# iqn_ail register map
Vendor: Texas Instruments
Registers are 32-bit, read-only, no defined reset value unless marked. A register's access mark holds for its fields unless they carry their own. Offsets are as the file gives them; [hi:lo] are bit positions; {n}, {i} and the like mark numbered series.

## IQN_AIL (part 3 of 5)
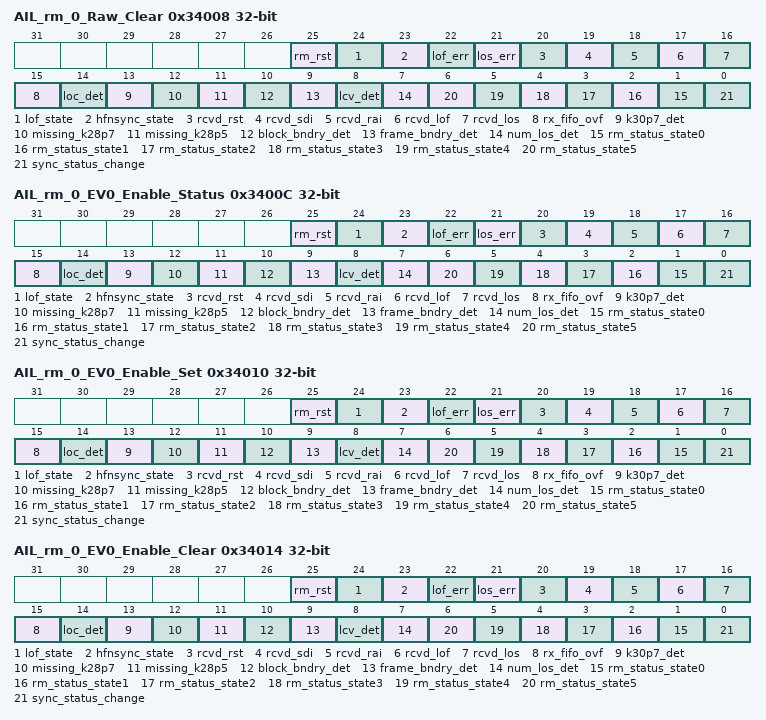
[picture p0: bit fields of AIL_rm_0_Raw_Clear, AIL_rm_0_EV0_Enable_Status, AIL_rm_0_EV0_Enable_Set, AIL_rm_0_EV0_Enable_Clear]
0x34008 AIL_rm_0_Raw_Clear wo — (1 of 1, stride 0)
  [25] rm_rst — Clears the corresponding bit in the raw_status register when set. Write only, self-clears.
  [24] lof_state — Clears the corresponding bit in the raw_status register when set. Write only, self-clears.
  [23] hfnsync_state — Clears the corresponding bit in the raw_status register when set. Write only, self-clears.
  [22] lof_err — Clears the corresponding bit in the raw_status register when set. Write only, self-clears.
  [21] los_err — Clears the corresponding bit in the raw_status register when set. Write only, self-clears.
  [20] rcvd_rst — Clears the corresponding bit in the raw_status register when set. Write only, self-clears.
  [19] rcvd_sdi — Clears the corresponding bit in the raw_status register when set. Write only, self-clears.
  [18] rcvd_rai — Clears the corresponding bit in the raw_status register when set. Write only, self-clears.
  [17] rcvd_lof — Clears the corresponding bit in the raw_status register when set. Write only, self-clears.
  [16] rcvd_los — Clears the corresponding bit in the raw_status register when set. Write only, self-clears.
  [15] rx_fifo_ovf — Clears the corresponding bit in the raw_status register when set. Write only, self-clears.
  [14] loc_det — Clears the corresponding bit in the raw_status register when set. Write only, self-clears.
  [13] k30p7_det — Clears the corresponding bit in the raw_status register when set. Write only, self-clears.
  [12] missing_k28p7 — Clears the corresponding bit in the raw_status register when set. Write only, self-clears.
  [11] missing_k28p5 — Clears the corresponding bit in the raw_status register when set. Write only, self-clears.
  [10] block_bndry_det — Clears the corresponding bit in the raw_status register when set. Write only, self-clears.
  [9] frame_bndry_det — Clears the corresponding bit in the raw_status register when set. Write only, self-clears.
  [8] lcv_det — Clears the corresponding bit in the raw_status register when set. Write only, self-clears.
  [7] num_los_det — Clears the corresponding bit in the raw_status register when set. Write only, self-clears.
  [n+1] rm_status_state{n} (n=0..5) — Clears the corresponding bit in the raw_status register when set. Write only, self-clears.
  [0] sync_status_change — Clears the corresponding bit in the raw_status register when set. Write only, self-clears.
0x3400C AIL_rm_0_EV0_Enable_Status — (1 of 1, stride 0)
  [25] rm_rst — When set allows the corresponding bit in the raw_status register to generate the intr_sts interrupt. Read only.
  [24] lof_state — When set allows the corresponding bit in the raw_status register to generate the intr_sts interrupt. Read only.
  [23] hfnsync_state — When set allows the corresponding bit in the raw_status register to generate the intr_sts interrupt. Read only.
  [22] lof_err — When set allows the corresponding bit in the raw_status register to generate the intr_sts interrupt. Read only.
  [21] los_err — When set allows the corresponding bit in the raw_status register to generate the intr_sts interrupt. Read only.
  [20] rcvd_rst — When set allows the corresponding bit in the raw_status register to generate the intr_sts interrupt. Read only.
  [19] rcvd_sdi — When set allows the corresponding bit in the raw_status register to generate the intr_sts interrupt. Read only.
  [18] rcvd_rai — When set allows the corresponding bit in the raw_status register to generate the intr_sts interrupt. Read only.
  [17] rcvd_lof — When set allows the corresponding bit in the raw_status register to generate the intr_sts interrupt. Read only.
  [16] rcvd_los — When set allows the corresponding bit in the raw_status register to generate the intr_sts interrupt. Read only.
  [15] rx_fifo_ovf — When set allows the corresponding bit in the raw_status register to generate the intr_sts interrupt. Read only.
  [14] loc_det — When set allows the corresponding bit in the raw_status register to generate the intr_sts interrupt. Read only.
  [13] k30p7_det — When set allows the corresponding bit in the raw_status register to generate the intr_sts interrupt. Read only.
  [12] missing_k28p7 — When set allows the corresponding bit in the raw_status register to generate the intr_sts interrupt. Read only.
  [11] missing_k28p5 — When set allows the corresponding bit in the raw_status register to generate the intr_sts interrupt. Read only.
  [10] block_bndry_det — When set allows the corresponding bit in the raw_status register to generate the intr_sts interrupt. Read only.
  [9] frame_bndry_det — When set allows the corresponding bit in the raw_status register to generate the intr_sts interrupt. Read only.
  [8] lcv_det — When set allows the corresponding bit in the raw_status register to generate the intr_sts interrupt. Read only.
  [7] num_los_det — When set allows the corresponding bit in the raw_status register to generate the intr_sts interrupt. Read only.
  [n+1] rm_status_state{n} (n=0..5) — When set allows the corresponding bit in the raw_status register to generate the intr_sts interrupt. Read only.
  [0] sync_status_change — When set allows the corresponding bit in the raw_status register to generate the intr_sts interrupt. Read only.
0x34010 AIL_rm_0_EV0_Enable_Set wo — (1 of 1, stride 0)
  [25] rm_rst — Sets the corresponding bit in the enable register when set. Write only, self-clears.
  [24] lof_state — Sets the corresponding bit in the enable register when set. Write only, self-clears.
  [23] hfnsync_state — Sets the corresponding bit in the enable register when set. Write only, self-clears.
  [22] lof_err — Sets the corresponding bit in the enable register when set. Write only, self-clears.
  [21] los_err — Sets the corresponding bit in the enable register when set. Write only, self-clears.
  [20] rcvd_rst — Sets the corresponding bit in the enable register when set. Write only, self-clears.
  [19] rcvd_sdi — Sets the corresponding bit in the enable register when set. Write only, self-clears.
  [18] rcvd_rai — Sets the corresponding bit in the enable register when set. Write only, self-clears.
  [17] rcvd_lof — Sets the corresponding bit in the enable register when set. Write only, self-clears.
  [16] rcvd_los — Sets the corresponding bit in the enable register when set. Write only, self-clears.
  [15] rx_fifo_ovf — Sets the corresponding bit in the enable register when set. Write only, self-clears.
  [14] loc_det — Sets the corresponding bit in the enable register when set. Write only, self-clears.
  [13] k30p7_det — Sets the corresponding bit in the enable register when set. Write only, self-clears.
  [12] missing_k28p7 — Sets the corresponding bit in the enable register when set. Write only, self-clears.
  [11] missing_k28p5 — Sets the corresponding bit in the enable register when set. Write only, self-clears.
  [10] block_bndry_det — Sets the corresponding bit in the enable register when set. Write only, self-clears.
  [9] frame_bndry_det — Sets the corresponding bit in the enable register when set. Write only, self-clears.
  [8] lcv_det — Sets the corresponding bit in the enable register when set. Write only, self-clears.
  [7] num_los_det — Sets the corresponding bit in the enable register when set. Write only, self-clears.
  [n+1] rm_status_state{n} (n=0..5) — Sets the corresponding bit in the enable register when set. Write only, self-clears.
  [0] sync_status_change — Sets the corresponding bit in the enable register when set. Write only, self-clears.
0x34014 AIL_rm_0_EV0_Enable_Clear wo — (1 of 1, stride 0)
  [25] rm_rst — Clears the corresponding bit in the enable register when set. Write only, self-clears.
  [24] lof_state — Clears the corresponding bit in the enable register when set. Write only, self-clears.
  [23] hfnsync_state — Clears the corresponding bit in the enable register when set. Write only, self-clears.
  [22] lof_err — Clears the corresponding bit in the enable register when set. Write only, self-clears.
  [21] los_err — Clears the corresponding bit in the enable register when set. Write only, self-clears.
  [20] rcvd_rst — Clears the corresponding bit in the enable register when set. Write only, self-clears.
  [19] rcvd_sdi — Clears the corresponding bit in the enable register when set. Write only, self-clears.
  [18] rcvd_rai — Clears the corresponding bit in the enable register when set. Write only, self-clears.
  [17] rcvd_lof — Clears the corresponding bit in the enable register when set. Write only, self-clears.
  [16] rcvd_los — Clears the corresponding bit in the enable register when set. Write only, self-clears.
  [15] rx_fifo_ovf — Clears the corresponding bit in the enable register when set. Write only, self-clears.
  [14] loc_det — Clears the corresponding bit in the enable register when set. Write only, self-clears.
  [13] k30p7_det — Clears the corresponding bit in the enable register when set. Write only, self-clears.
  [12] missing_k28p7 — Clears the corresponding bit in the enable register when set. Write only, self-clears.
  [11] missing_k28p5 — Clears the corresponding bit in the enable register when set. Write only, self-clears.
  [10] block_bndry_det — Clears the corresponding bit in the enable register when set. Write only, self-clears.
  [9] frame_bndry_det — Clears the corresponding bit in the enable register when set. Write only, self-clears.
  [8] lcv_det — Clears the corresponding bit in the enable register when set. Write only, self-clears.
  [7] num_los_det — Clears the corresponding bit in the enable register when set. Write only, self-clears.
  [n+1] rm_status_state{n} (n=0..5) — Clears the corresponding bit in the enable register when set. Write only, self-clears.
  [0] sync_status_change — Clears the corresponding bit in the enable register when set. Write only, self-clears.
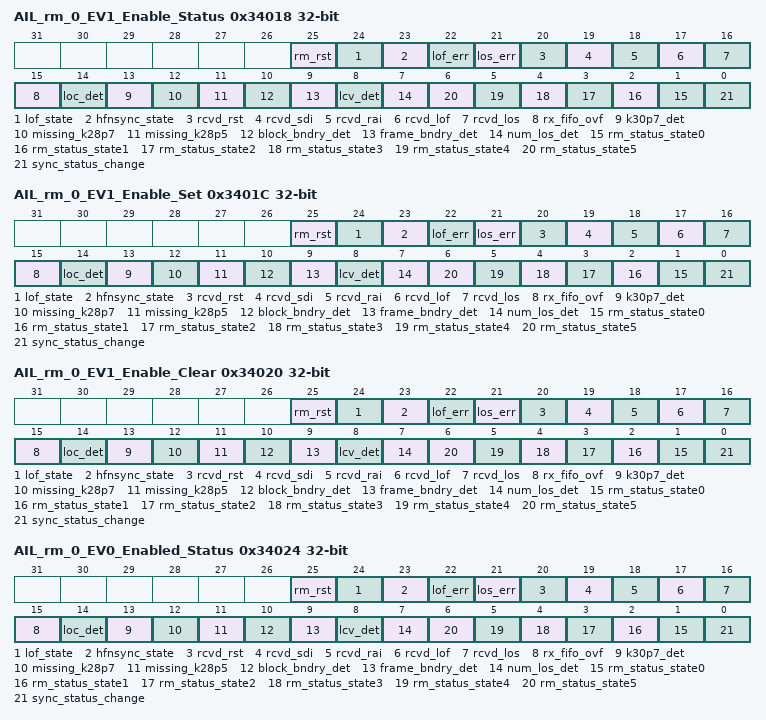
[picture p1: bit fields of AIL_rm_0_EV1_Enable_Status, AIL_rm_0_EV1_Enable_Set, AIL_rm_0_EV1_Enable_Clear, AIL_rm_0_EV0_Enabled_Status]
0x34018 AIL_rm_0_EV1_Enable_Status — (1 of 1, stride 0)
  [25] rm_rst — When set allows the corresponding bit in the raw_status register to generate the intr1_sts interrupt. Read only.
  [24] lof_state — When set allows the corresponding bit in the raw_status register to generate the intr1_sts interrupt. Read only.
  [23] hfnsync_state — When set allows the corresponding bit in the raw_status register to generate the intr1_sts interrupt. Read only.
  [22] lof_err — When set allows the corresponding bit in the raw_status register to generate the intr1_sts interrupt. Read only.
  [21] los_err — When set allows the corresponding bit in the raw_status register to generate the intr1_sts interrupt. Read only.
  [20] rcvd_rst — When set allows the corresponding bit in the raw_status register to generate the intr1_sts interrupt. Read only.
  [19] rcvd_sdi — When set allows the corresponding bit in the raw_status register to generate the intr1_sts interrupt. Read only.
  [18] rcvd_rai — When set allows the corresponding bit in the raw_status register to generate the intr1_sts interrupt. Read only.
  [17] rcvd_lof — When set allows the corresponding bit in the raw_status register to generate the intr1_sts interrupt. Read only.
  [16] rcvd_los — When set allows the corresponding bit in the raw_status register to generate the intr1_sts interrupt. Read only.
  [15] rx_fifo_ovf — When set allows the corresponding bit in the raw_status register to generate the intr1_sts interrupt. Read only.
  [14] loc_det — When set allows the corresponding bit in the raw_status register to generate the intr1_sts interrupt. Read only.
  [13] k30p7_det — When set allows the corresponding bit in the raw_status register to generate the intr1_sts interrupt. Read only.
  [12] missing_k28p7 — When set allows the corresponding bit in the raw_status register to generate the intr1_sts interrupt. Read only.
  [11] missing_k28p5 — When set allows the corresponding bit in the raw_status register to generate the intr1_sts interrupt. Read only.
  [10] block_bndry_det — When set allows the corresponding bit in the raw_status register to generate the intr1_sts interrupt. Read only.
  [9] frame_bndry_det — When set allows the corresponding bit in the raw_status register to generate the intr1_sts interrupt. Read only.
  [8] lcv_det — When set allows the corresponding bit in the raw_status register to generate the intr1_sts interrupt. Read only.
  [7] num_los_det — When set allows the corresponding bit in the raw_status register to generate the intr1_sts interrupt. Read only.
  [n+1] rm_status_state{n} (n=0..5) — When set allows the corresponding bit in the raw_status register to generate the intr1_sts interrupt. Read only.
  [0] sync_status_change — When set allows the corresponding bit in the raw_status register to generate the intr1_sts interrupt. Read only.
0x3401C AIL_rm_0_EV1_Enable_Set wo — (1 of 1, stride 0)
  [25] rm_rst — Sets the corresponding bit in the intr1_status register when set. Write only, self-clears.
  [24] lof_state — Sets the corresponding bit in the intr1_status register when set. Write only, self-clears.
  [23] hfnsync_state — Sets the corresponding bit in the intr1_status register when set. Write only, self-clears.
  [22] lof_err — Sets the corresponding bit in the intr1_status register when set. Write only, self-clears.
  [21] los_err — Sets the corresponding bit in the intr1_status register when set. Write only, self-clears.
  [20] rcvd_rst — Sets the corresponding bit in the intr1_status register when set. Write only, self-clears.
  [19] rcvd_sdi — Sets the corresponding bit in the intr1_status register when set. Write only, self-clears.
  [18] rcvd_rai — Sets the corresponding bit in the intr1_status register when set. Write only, self-clears.
  [17] rcvd_lof — Sets the corresponding bit in the intr1_status register when set. Write only, self-clears.
  [16] rcvd_los — Sets the corresponding bit in the intr1_status register when set. Write only, self-clears.
  [15] rx_fifo_ovf — Sets the corresponding bit in the intr1_status register when set. Write only, self-clears.
  [14] loc_det — Sets the corresponding bit in the intr1_status register when set. Write only, self-clears.
  [13] k30p7_det — Sets the corresponding bit in the intr1_status register when set. Write only, self-clears.
  [12] missing_k28p7 — Sets the corresponding bit in the intr1_status register when set. Write only, self-clears.
  [11] missing_k28p5 — Sets the corresponding bit in the intr1_status register when set. Write only, self-clears.
  [10] block_bndry_det — Sets the corresponding bit in the intr1_status register when set. Write only, self-clears.
  [9] frame_bndry_det — Sets the corresponding bit in the intr1_status register when set. Write only, self-clears.
  [8] lcv_det — Sets the corresponding bit in the intr1_status register when set. Write only, self-clears.
  [7] num_los_det — Sets the corresponding bit in the intr1_status register when set. Write only, self-clears.
  [n+1] rm_status_state{n} (n=0..5) — Sets the corresponding bit in the intr1_status register when set. Write only, self-clears.
  [0] sync_status_change — Sets the corresponding bit in the intr1_status register when set. Write only, self-clears.
0x34020 AIL_rm_0_EV1_Enable_Clear wo — (1 of 1, stride 0)
  [25] rm_rst — Clears the corresponding bit in the intr1_status register when set. Write only, self-clears.
  [24] lof_state — Clears the corresponding bit in the intr1_status register when set. Write only, self-clears.
  [23] hfnsync_state — Clears the corresponding bit in the intr1_status register when set. Write only, self-clears.
  [22] lof_err — Clears the corresponding bit in the intr1_status register when set. Write only, self-clears.
  [21] los_err — Clears the corresponding bit in the intr1_status register when set. Write only, self-clears.
  [20] rcvd_rst — Clears the corresponding bit in the intr1_status register when set. Write only, self-clears.
  [19] rcvd_sdi — Clears the corresponding bit in the intr1_status register when set. Write only, self-clears.
  [18] rcvd_rai — Clears the corresponding bit in the intr1_status register when set. Write only, self-clears.
  [17] rcvd_lof — Clears the corresponding bit in the intr1_status register when set. Write only, self-clears.
  [16] rcvd_los — Clears the corresponding bit in the intr1_status register when set. Write only, self-clears.
  [15] rx_fifo_ovf — Clears the corresponding bit in the intr1_status register when set. Write only, self-clears.
  [14] loc_det — Clears the corresponding bit in the intr1_status register when set. Write only, self-clears.
  [13] k30p7_det — Clears the corresponding bit in the intr1_status register when set. Write only, self-clears.
  [12] missing_k28p7 — Clears the corresponding bit in the intr1_status register when set. Write only, self-clears.
  [11] missing_k28p5 — Clears the corresponding bit in the intr1_status register when set. Write only, self-clears.
  [10] block_bndry_det — Clears the corresponding bit in the intr1_status register when set. Write only, self-clears.
  [9] frame_bndry_det — Clears the corresponding bit in the intr1_status register when set. Write only, self-clears.
  [8] lcv_det — Clears the corresponding bit in the intr1_status register when set. Write only, self-clears.
  [7] num_los_det — Clears the corresponding bit in the intr1_status register when set. Write only, self-clears.
  [n+1] rm_status_state{n} (n=0..5) — Clears the corresponding bit in the intr1_status register when set. Write only, self-clears.
  [0] sync_status_change — Clears the corresponding bit in the intr1_status register when set. Write only, self-clears.
0x34024 AIL_rm_0_EV0_Enabled_Status — (1 of 1, stride 0)
  [25] rm_rst — AND-ed raw_status bits with the corresponding bit in the enable_status register. Read only.
  [24] lof_state — AND-ed raw_status bits with the corresponding bit in the enable_status register. Read only.
  [23] hfnsync_state — AND-ed raw_status bits with the corresponding bit in the enable_status register. Read only.
  [22] lof_err — AND-ed raw_status bits with the corresponding bit in the enable_status register. Read only.
  [21] los_err — AND-ed raw_status bits with the corresponding bit in the enable_status register. Read only.
  [20] rcvd_rst — AND-ed raw_status bits with the corresponding bit in the enable_status register. Read only.
  [19] rcvd_sdi — AND-ed raw_status bits with the corresponding bit in the enable_status register. Read only.
  [18] rcvd_rai — AND-ed raw_status bits with the corresponding bit in the enable_status register. Read only.
  [17] rcvd_lof — AND-ed raw_status bits with the corresponding bit in the enable_status register. Read only.
  [16] rcvd_los — AND-ed raw_status bits with the corresponding bit in the enable_status register. Read only.
  [15] rx_fifo_ovf — AND-ed raw_status bits with the corresponding bit in the enable_status register. Read only.
  [14] loc_det — AND-ed raw_status bits with the corresponding bit in the enable_status register. Read only.
  [13] k30p7_det — AND-ed raw_status bits with the corresponding bit in the enable_status register. Read only.
  [12] missing_k28p7 — AND-ed raw_status bits with the corresponding bit in the enable_status register. Read only.
  [11] missing_k28p5 — AND-ed raw_status bits with the corresponding bit in the enable_status register. Read only.
  [10] block_bndry_det — AND-ed raw_status bits with the corresponding bit in the enable_status register. Read only.
  [9] frame_bndry_det — AND-ed raw_status bits with the corresponding bit in the enable_status register. Read only.
  [8] lcv_det — AND-ed raw_status bits with the corresponding bit in the enable_status register. Read only.
  [7] num_los_det — AND-ed raw_status bits with the corresponding bit in the enable_status register. Read only.
  [n+1] rm_status_state{n} (n=0..5) — AND-ed raw_status bits with the corresponding bit in the enable_status register. Read only.
  [0] sync_status_change — AND-ed raw_status bits with the corresponding bit in the enable_status register. Read only.
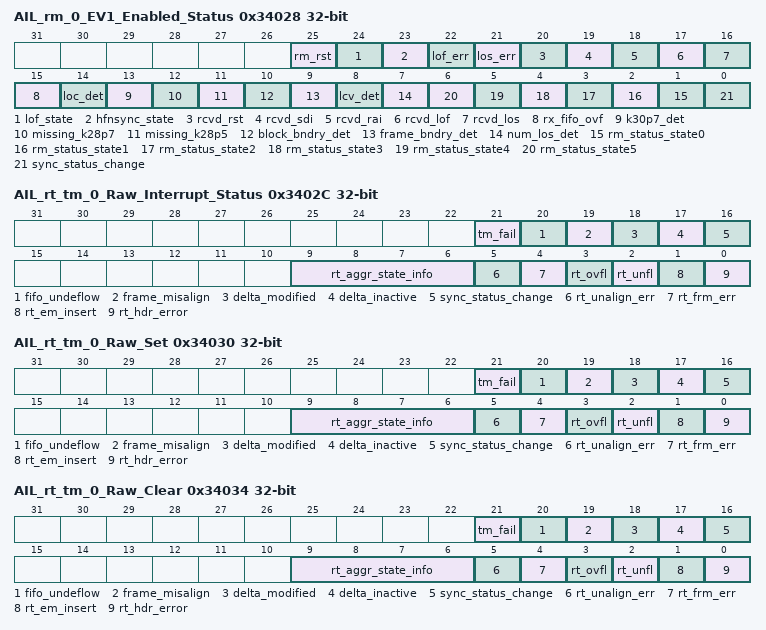
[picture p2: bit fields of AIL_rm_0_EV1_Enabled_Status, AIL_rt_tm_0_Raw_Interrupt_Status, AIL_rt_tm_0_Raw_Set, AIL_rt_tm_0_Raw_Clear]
0x34028 AIL_rm_0_EV1_Enabled_Status — (1 of 1, stride 0)
  [25] rm_rst — AND-ed raw_status bits with the corresponding bit in the intr1_status register. Read only.
  [24] lof_state — AND-ed raw_status bits with the corresponding bit in the intr1_status register. Read only.
  [23] hfnsync_state — AND-ed raw_status bits with the corresponding bit in the intr1_status register. Read only.
  [22] lof_err — AND-ed raw_status bits with the corresponding bit in the intr1_status register. Read only.
  [21] los_err — AND-ed raw_status bits with the corresponding bit in the intr1_status register. Read only.
  [20] rcvd_rst — AND-ed raw_status bits with the corresponding bit in the intr1_status register. Read only.
  [19] rcvd_sdi — AND-ed raw_status bits with the corresponding bit in the intr1_status register. Read only.
  [18] rcvd_rai — AND-ed raw_status bits with the corresponding bit in the intr1_status register. Read only.
  [17] rcvd_lof — AND-ed raw_status bits with the corresponding bit in the intr1_status register. Read only.
  [16] rcvd_los — AND-ed raw_status bits with the corresponding bit in the intr1_status register. Read only.
  [15] rx_fifo_ovf — AND-ed raw_status bits with the corresponding bit in the intr1_status register. Read only.
  [14] loc_det — AND-ed raw_status bits with the corresponding bit in the intr1_status register. Read only.
  [13] k30p7_det — AND-ed raw_status bits with the corresponding bit in the intr1_status register. Read only.
  [12] missing_k28p7 — AND-ed raw_status bits with the corresponding bit in the intr1_status register. Read only.
  [11] missing_k28p5 — AND-ed raw_status bits with the corresponding bit in the intr1_status register. Read only.
  [10] block_bndry_det — AND-ed raw_status bits with the corresponding bit in the intr1_status register. Read only.
  [9] frame_bndry_det — AND-ed raw_status bits with the corresponding bit in the intr1_status register. Read only.
  [8] lcv_det — AND-ed raw_status bits with the corresponding bit in the intr1_status register. Read only.
  [7] num_los_det — AND-ed raw_status bits with the corresponding bit in the intr1_status register. Read only.
  [n+1] rm_status_state{n} (n=0..5) — AND-ed raw_status bits with the corresponding bit in the intr1_status register. Read only.
  [0] sync_status_change — AND-ed raw_status bits with the corresponding bit in the intr1_status register. Read only.
0x3402C AIL_rt_tm_0_Raw_Interrupt_Status — (1 of 1, stride 0)
  [21] tm_fail — TM Failure indicates that the tm has forced the upstream logic to flush data buffers and resynchronize to a new frame boundary.
  [20] fifo_undeflow — TM Fifo underflowed.
  [19] frame_misalign — TM detected a frame misalignment in the signal it receives from the CO.
  [18] delta_modified — TM detected that the frame strobe from the micro-at was received earlier than expected.
  [17] delta_inactive — TM detected that the frame strobe from the micro-at seems inactive compared to the Tx state machine and link configuration.
  [16] sync_status_change — TM detected a change in sync status. The actual frame status can be found in the TM status register
  [9:6] rt_aggr_state_info — RT aggregation state info bit 0 = aggr_init, bit 1 = aggr_pe, bit 2 = aggr_rm, bit 3 = aggr_pe_rm.
  [5] rt_unalign_err — RT detected the alignment window is too large in RE ULNK mode.
  [4] rt_frm_err — RT detected a framing error from either the CI input or the PE input.
  [3] rt_ovfl — RT FIFO Overflow.
  [2] rt_unfl — RT FIFO Underflow.
  [1] rt_em_insert — RT inserted an empty message.
  [0] rt_hdr_error — RT detected an error in the header.
0x34030 AIL_rt_tm_0_Raw_Set wo — (1 of 1, stride 0)
  [21] tm_fail — Sets the corresponding bit in the raw_status register when set. Write only, self-clears.
  [20] fifo_undeflow — Sets the corresponding bit in the raw_status register when set. Write only, self-clears.
  [19] frame_misalign — Sets the corresponding bit in the raw_status register when set. Write only, self-clears.
  [18] delta_modified — Sets the corresponding bit in the raw_status register when set. Write only, self-clears.
  [17] delta_inactive — Sets the corresponding bit in the raw_status register when set. Write only, self-clears.
  [16] sync_status_change — Sets the corresponding bit in the raw_status register when set. Write only, self-clears.
  [9:6] rt_aggr_state_info — Sets the corresponding bit in the raw_status register when set. Write only, self-clears.
  [5] rt_unalign_err — Sets the corresponding bit in the raw_status register when set. Write only, self-clears.
  [4] rt_frm_err — Sets the corresponding bit in the raw_status register when set. Write only, self-clears.
  [3] rt_ovfl — Sets the corresponding bit in the raw_status register when set. Write only, self-clears.
  [2] rt_unfl — Sets the corresponding bit in the raw_status register when set. Write only, self-clears.
  [1] rt_em_insert — Sets the corresponding bit in the raw_status register when set. Write only, self-clears.
  [0] rt_hdr_error — Sets the corresponding bit in the raw_status register when set. Write only, self-clears.
0x34034 AIL_rt_tm_0_Raw_Clear wo — (1 of 1, stride 0)
  [21] tm_fail — Clears the corresponding bit in the raw_status register when set. Write only, self-clears.
  [20] fifo_undeflow — Clears the corresponding bit in the raw_status register when set. Write only, self-clears.
  [19] frame_misalign — Clears the corresponding bit in the raw_status register when set. Write only, self-clears.
  [18] delta_modified — Clears the corresponding bit in the raw_status register when set. Write only, self-clears.
  [17] delta_inactive — Clears the corresponding bit in the raw_status register when set. Write only, self-clears.
  [16] sync_status_change — Clears the corresponding bit in the raw_status register when set. Write only, self-clears.
  [9:6] rt_aggr_state_info — Clears the corresponding bit in the raw_status register when set. Write only, self-clears.
  [5] rt_unalign_err — Clears the corresponding bit in the raw_status register when set. Write only, self-clears.
  [4] rt_frm_err — Clears the corresponding bit in the raw_status register when set. Write only, self-clears.
  [3] rt_ovfl — Clears the corresponding bit in the raw_status register when set. Write only, self-clears.
  [2] rt_unfl — Clears the corresponding bit in the raw_status register when set. Write only, self-clears.
  [1] rt_em_insert — Clears the corresponding bit in the raw_status register when set. Write only, self-clears.
  [0] rt_hdr_error — Clears the corresponding bit in the raw_status register when set. Write only, self-clears.
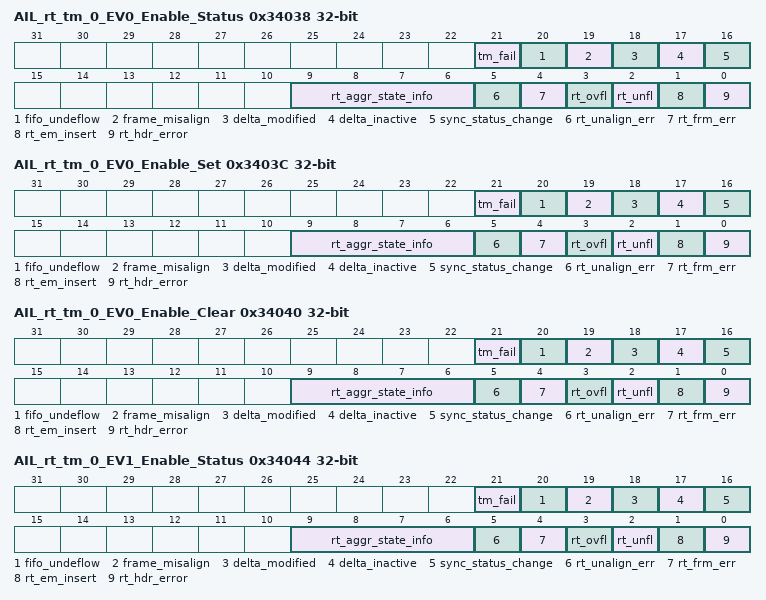
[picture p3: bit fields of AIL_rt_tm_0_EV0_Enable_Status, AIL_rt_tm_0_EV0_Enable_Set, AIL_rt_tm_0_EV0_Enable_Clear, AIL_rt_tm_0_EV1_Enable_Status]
0x34038 AIL_rt_tm_0_EV0_Enable_Status — (1 of 1, stride 0)
  [21] tm_fail — When set allows the corresponding bit in the raw_status register to generate the intr_sts interrupt. Read only.
  [20] fifo_undeflow — When set allows the corresponding bit in the raw_status register to generate the intr_sts interrupt. Read only.
  [19] frame_misalign — When set allows the corresponding bit in the raw_status register to generate the intr_sts interrupt. Read only.
  [18] delta_modified — When set allows the corresponding bit in the raw_status register to generate the intr_sts interrupt. Read only.
  [17] delta_inactive — When set allows the corresponding bit in the raw_status register to generate the intr_sts interrupt. Read only.
  [16] sync_status_change — When set allows the corresponding bit in the raw_status register to generate the intr_sts interrupt. Read only.
  [9:6] rt_aggr_state_info — When set allows the corresponding bit in the raw_status register to generate the intr_sts interrupt. Read only.
  [5] rt_unalign_err — When set allows the corresponding bit in the raw_status register to generate the intr_sts interrupt. Read only.
  [4] rt_frm_err — When set allows the corresponding bit in the raw_status register to generate the intr_sts interrupt. Read only.
  [3] rt_ovfl — When set allows the corresponding bit in the raw_status register to generate the intr_sts interrupt. Read only.
  [2] rt_unfl — When set allows the corresponding bit in the raw_status register to generate the intr_sts interrupt. Read only.
  [1] rt_em_insert — When set allows the corresponding bit in the raw_status register to generate the intr_sts interrupt. Read only.
  [0] rt_hdr_error — When set allows the corresponding bit in the raw_status register to generate the intr_sts interrupt. Read only.
0x3403C AIL_rt_tm_0_EV0_Enable_Set wo — (1 of 1, stride 0)
  [21] tm_fail — Sets the corresponding bit in the enable register when set. Write only, self-clears.
  [20] fifo_undeflow — Sets the corresponding bit in the enable register when set. Write only, self-clears.
  [19] frame_misalign — Sets the corresponding bit in the enable register when set. Write only, self-clears.
  [18] delta_modified — Sets the corresponding bit in the enable register when set. Write only, self-clears.
  [17] delta_inactive — Sets the corresponding bit in the enable register when set. Write only, self-clears.
  [16] sync_status_change — Sets the corresponding bit in the enable register when set. Write only, self-clears.
  [9:6] rt_aggr_state_info — Sets the corresponding bit in the enable register when set. Write only, self-clears.
  [5] rt_unalign_err — Sets the corresponding bit in the enable register when set. Write only, self-clears.
  [4] rt_frm_err — Sets the corresponding bit in the enable register when set. Write only, self-clears.
  [3] rt_ovfl — Sets the corresponding bit in the enable register when set. Write only, self-clears.
  [2] rt_unfl — Sets the corresponding bit in the enable register when set. Write only, self-clears.
  [1] rt_em_insert — Sets the corresponding bit in the enable register when set. Write only, self-clears.
  [0] rt_hdr_error — Sets the corresponding bit in the enable register when set. Write only, self-clears.
0x34040 AIL_rt_tm_0_EV0_Enable_Clear wo — (1 of 1, stride 0)
  [21] tm_fail — Clears the corresponding bit in the enable register when set. Write only, self-clears.
  [20] fifo_undeflow — Clears the corresponding bit in the enable register when set. Write only, self-clears.
  [19] frame_misalign — Clears the corresponding bit in the enable register when set. Write only, self-clears.
  [18] delta_modified — Clears the corresponding bit in the enable register when set. Write only, self-clears.
  [17] delta_inactive — Clears the corresponding bit in the enable register when set. Write only, self-clears.
  [16] sync_status_change — Clears the corresponding bit in the enable register when set. Write only, self-clears.
  [9:6] rt_aggr_state_info — Clears the corresponding bit in the enable register when set. Write only, self-clears.
  [5] rt_unalign_err — Clears the corresponding bit in the enable register when set. Write only, self-clears.
  [4] rt_frm_err — Clears the corresponding bit in the enable register when set. Write only, self-clears.
  [3] rt_ovfl — Clears the corresponding bit in the enable register when set. Write only, self-clears.
  [2] rt_unfl — Clears the corresponding bit in the enable register when set. Write only, self-clears.
  [1] rt_em_insert — Clears the corresponding bit in the enable register when set. Write only, self-clears.
  [0] rt_hdr_error — Clears the corresponding bit in the enable register when set. Write only, self-clears.
0x34044 AIL_rt_tm_0_EV1_Enable_Status — (1 of 1, stride 0)
  [21] tm_fail — When set allows the corresponding bit in the raw_status register to generate the intr1_sts interrupt. Read only.
  [20] fifo_undeflow — When set allows the corresponding bit in the raw_status register to generate the intr1_sts interrupt. Read only.
  [19] frame_misalign — When set allows the corresponding bit in the raw_status register to generate the intr1_sts interrupt. Read only.
  [18] delta_modified — When set allows the corresponding bit in the raw_status register to generate the intr1_sts interrupt. Read only.
  [17] delta_inactive — When set allows the corresponding bit in the raw_status register to generate the intr1_sts interrupt. Read only.
  [16] sync_status_change — When set allows the corresponding bit in the raw_status register to generate the intr1_sts interrupt. Read only.
  [9:6] rt_aggr_state_info — When set allows the corresponding bit in the raw_status register to generate the intr1_sts interrupt. Read only.
  [5] rt_unalign_err — When set allows the corresponding bit in the raw_status register to generate the intr1_sts interrupt. Read only.
  [4] rt_frm_err — When set allows the corresponding bit in the raw_status register to generate the intr1_sts interrupt. Read only.
  [3] rt_ovfl — When set allows the corresponding bit in the raw_status register to generate the intr1_sts interrupt. Read only.
  [2] rt_unfl — When set allows the corresponding bit in the raw_status register to generate the intr1_sts interrupt. Read only.
  [1] rt_em_insert — When set allows the corresponding bit in the raw_status register to generate the intr1_sts interrupt. Read only.
  [0] rt_hdr_error — When set allows the corresponding bit in the raw_status register to generate the intr1_sts interrupt. Read only.
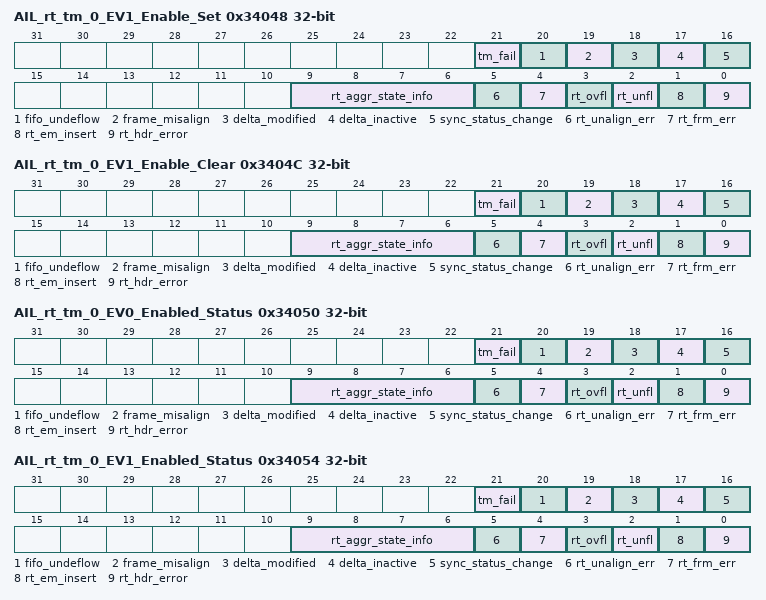
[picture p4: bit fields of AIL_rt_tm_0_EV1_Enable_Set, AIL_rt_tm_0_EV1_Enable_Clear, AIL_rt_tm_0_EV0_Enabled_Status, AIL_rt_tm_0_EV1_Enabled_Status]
0x34048 AIL_rt_tm_0_EV1_Enable_Set wo — (1 of 1, stride 0)
  [21] tm_fail — Sets the corresponding bit in the intr1_status register when set. Write only, self-clears.
  [20] fifo_undeflow — Sets the corresponding bit in the intr1_status register when set. Write only, self-clears.
  [19] frame_misalign — Sets the corresponding bit in the intr1_status register when set. Write only, self-clears.
  [18] delta_modified — Sets the corresponding bit in the intr1_status register when set. Write only, self-clears.
  [17] delta_inactive — Sets the corresponding bit in the intr1_status register when set. Write only, self-clears.
  [16] sync_status_change — Sets the corresponding bit in the intr1_status register when set. Write only, self-clears.
  [9:6] rt_aggr_state_info — Sets the corresponding bit in the intr1_status register when set. Write only, self-clears.
  [5] rt_unalign_err — Sets the corresponding bit in the intr1_status register when set. Write only, self-clears.
  [4] rt_frm_err — Sets the corresponding bit in the intr1_status register when set. Write only, self-clears.
  [3] rt_ovfl — Sets the corresponding bit in the intr1_status register when set. Write only, self-clears.
  [2] rt_unfl — Sets the corresponding bit in the intr1_status register when set. Write only, self-clears.
  [1] rt_em_insert — Sets the corresponding bit in the intr1_status register when set. Write only, self-clears.
  [0] rt_hdr_error — Sets the corresponding bit in the intr1_status register when set. Write only, self-clears.
0x3404C AIL_rt_tm_0_EV1_Enable_Clear wo — (1 of 1, stride 0)
  [21] tm_fail — Clears the corresponding bit in the intr1_status register when set. Write only, self-clears.
  [20] fifo_undeflow — Clears the corresponding bit in the intr1_status register when set. Write only, self-clears.
  [19] frame_misalign — Clears the corresponding bit in the intr1_status register when set. Write only, self-clears.
  [18] delta_modified — Clears the corresponding bit in the intr1_status register when set. Write only, self-clears.
  [17] delta_inactive — Clears the corresponding bit in the intr1_status register when set. Write only, self-clears.
  [16] sync_status_change — Clears the corresponding bit in the intr1_status register when set. Write only, self-clears.
  [9:6] rt_aggr_state_info — Clears the corresponding bit in the intr1_status register when set. Write only, self-clears.
  [5] rt_unalign_err — Clears the corresponding bit in the intr1_status register when set. Write only, self-clears.
  [4] rt_frm_err — Clears the corresponding bit in the intr1_status register when set. Write only, self-clears.
  [3] rt_ovfl — Clears the corresponding bit in the intr1_status register when set. Write only, self-clears.
  [2] rt_unfl — Clears the corresponding bit in the intr1_status register when set. Write only, self-clears.
  [1] rt_em_insert — Clears the corresponding bit in the intr1_status register when set. Write only, self-clears.
  [0] rt_hdr_error — Clears the corresponding bit in the intr1_status register when set. Write only, self-clears.
0x34050 AIL_rt_tm_0_EV0_Enabled_Status — (1 of 1, stride 0)
  [21] tm_fail — AND-ed raw_status bits with the corresponding bit in the enable_status register. Read only.
  [20] fifo_undeflow — AND-ed raw_status bits with the corresponding bit in the enable_status register. Read only.
  [19] frame_misalign — AND-ed raw_status bits with the corresponding bit in the enable_status register. Read only.
  [18] delta_modified — AND-ed raw_status bits with the corresponding bit in the enable_status register. Read only.
  [17] delta_inactive — AND-ed raw_status bits with the corresponding bit in the enable_status register. Read only.
  [16] sync_status_change — AND-ed raw_status bits with the corresponding bit in the enable_status register. Read only.
  [9:6] rt_aggr_state_info — AND-ed raw_status bits with the corresponding bit in the enable_status register. Read only.
  [5] rt_unalign_err — AND-ed raw_status bits with the corresponding bit in the enable_status register. Read only.
  [4] rt_frm_err — AND-ed raw_status bits with the corresponding bit in the enable_status register. Read only.
  [3] rt_ovfl — AND-ed raw_status bits with the corresponding bit in the enable_status register. Read only.
  [2] rt_unfl — AND-ed raw_status bits with the corresponding bit in the enable_status register. Read only.
  [1] rt_em_insert — AND-ed raw_status bits with the corresponding bit in the enable_status register. Read only.
  [0] rt_hdr_error — AND-ed raw_status bits with the corresponding bit in the enable_status register. Read only.
0x34054 AIL_rt_tm_0_EV1_Enabled_Status — (1 of 1, stride 0)
  [21] tm_fail — AND-ed raw_status bits with the corresponding bit in the intr1_status register. Read only.
  [20] fifo_undeflow — AND-ed raw_status bits with the corresponding bit in the intr1_status register. Read only.
  [19] frame_misalign — AND-ed raw_status bits with the corresponding bit in the intr1_status register. Read only.
  [18] delta_modified — AND-ed raw_status bits with the corresponding bit in the intr1_status register. Read only.
  [17] delta_inactive — AND-ed raw_status bits with the corresponding bit in the intr1_status register. Read only.
  [16] sync_status_change — AND-ed raw_status bits with the corresponding bit in the intr1_status register. Read only.
  [9:6] rt_aggr_state_info — AND-ed raw_status bits with the corresponding bit in the intr1_status register. Read only.
  [5] rt_unalign_err — AND-ed raw_status bits with the corresponding bit in the intr1_status register. Read only.
  [4] rt_frm_err — AND-ed raw_status bits with the corresponding bit in the intr1_status register. Read only.
  [3] rt_ovfl — AND-ed raw_status bits with the corresponding bit in the intr1_status register. Read only.
  [2] rt_unfl — AND-ed raw_status bits with the corresponding bit in the intr1_status register. Read only.
  [1] rt_em_insert — AND-ed raw_status bits with the corresponding bit in the intr1_status register. Read only.
  [0] rt_hdr_error — AND-ed raw_status bits with the corresponding bit in the intr1_status register. Read only.
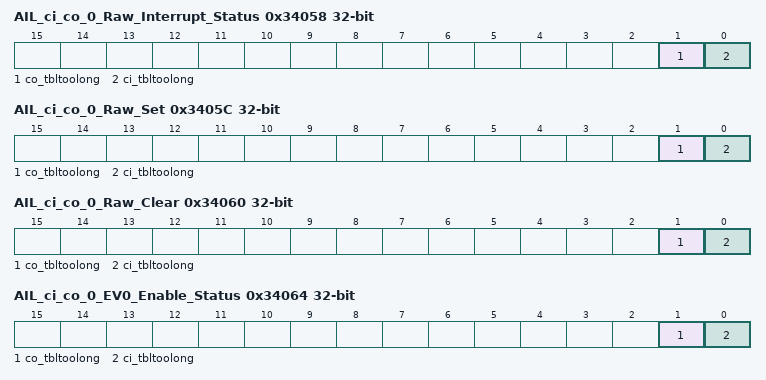
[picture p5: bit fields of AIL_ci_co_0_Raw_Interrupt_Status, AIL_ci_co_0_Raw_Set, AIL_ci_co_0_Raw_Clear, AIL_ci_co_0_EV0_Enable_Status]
0x34058 AIL_ci_co_0_Raw_Interrupt_Status — (1 of 1, stride 0)
  [1] co_tbltoolong — CO AXC Group LUT requested more containers transferred in a basic frame than can fit.
  [0] ci_tbltoolong — CI AXC Group LUT requested more containers transferred in a basic frame than can fit.
0x3405C AIL_ci_co_0_Raw_Set wo — (1 of 1, stride 0)
  [1] co_tbltoolong — Sets the corresponding bit in the raw_status register when set. Write only, self-clears.
  [0] ci_tbltoolong — Sets the corresponding bit in the raw_status register when set. Write only, self-clears.
0x34060 AIL_ci_co_0_Raw_Clear wo — (1 of 1, stride 0)
  [1] co_tbltoolong — Clears the corresponding bit in the raw_status register when set. Write only, self-clears.
  [0] ci_tbltoolong — Clears the corresponding bit in the raw_status register when set. Write only, self-clears.
0x34064 AIL_ci_co_0_EV0_Enable_Status — (1 of 1, stride 0)
  [1] co_tbltoolong — When set allows the corresponding bit in the raw_status register to generate the intr_sts interrupt. Read only.
  [0] ci_tbltoolong — When set allows the corresponding bit in the raw_status register to generate the intr_sts interrupt. Read only.
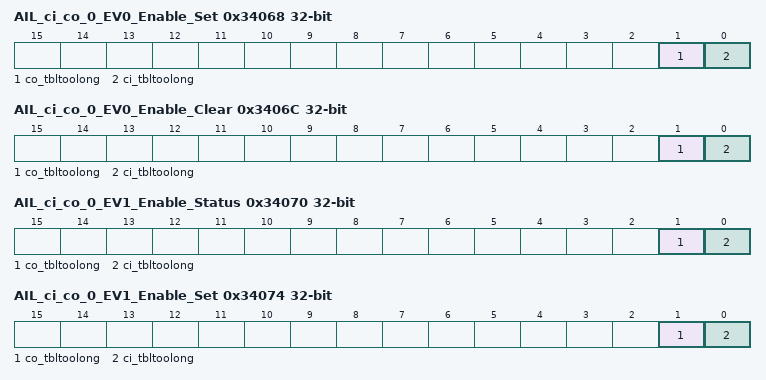
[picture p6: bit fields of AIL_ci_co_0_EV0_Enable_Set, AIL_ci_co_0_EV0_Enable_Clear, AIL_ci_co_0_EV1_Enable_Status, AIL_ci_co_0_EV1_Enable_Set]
0x34068 AIL_ci_co_0_EV0_Enable_Set wo — (1 of 1, stride 0)
  [1] co_tbltoolong — Sets the corresponding bit in the enable register when set. Write only, self-clears.
  [0] ci_tbltoolong — Sets the corresponding bit in the enable register when set. Write only, self-clears.
0x3406C AIL_ci_co_0_EV0_Enable_Clear wo — (1 of 1, stride 0)
  [1] co_tbltoolong — Clears the corresponding bit in the enable register when set. Write only, self-clears.
  [0] ci_tbltoolong — Clears the corresponding bit in the enable register when set. Write only, self-clears.
0x34070 AIL_ci_co_0_EV1_Enable_Status — (1 of 1, stride 0)
  [1] co_tbltoolong — When set allows the corresponding bit in the raw_status register to generate the intr1_sts interrupt. Read only.
  [0] ci_tbltoolong — When set allows the corresponding bit in the raw_status register to generate the intr1_sts interrupt. Read only.
0x34074 AIL_ci_co_0_EV1_Enable_Set wo — (1 of 1, stride 0)
  [1] co_tbltoolong — Sets the corresponding bit in the intr1_status register when set. Write only, self-clears.
  [0] ci_tbltoolong — Sets the corresponding bit in the intr1_status register when set. Write only, self-clears.
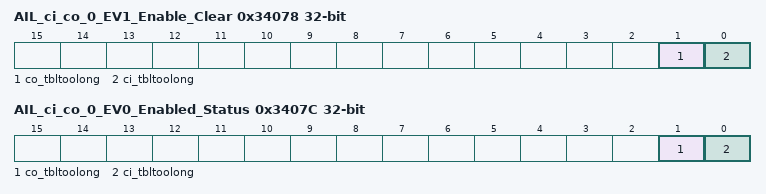
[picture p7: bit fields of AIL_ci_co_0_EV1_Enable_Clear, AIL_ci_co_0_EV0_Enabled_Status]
0x34078 AIL_ci_co_0_EV1_Enable_Clear wo — (1 of 1, stride 0)
  [1] co_tbltoolong — Clears the corresponding bit in the intr1_status register when set. Write only, self-clears.
  [0] ci_tbltoolong — Clears the corresponding bit in the intr1_status register when set. Write only, self-clears.
0x3407C AIL_ci_co_0_EV0_Enabled_Status — (1 of 1, stride 0)
  [1] co_tbltoolong — AND-ed raw_status bits with the corresponding bit in the enable_status register. Read only.
  [0] ci_tbltoolong — AND-ed raw_status bits with the corresponding bit in the enable_status register. Read only.
